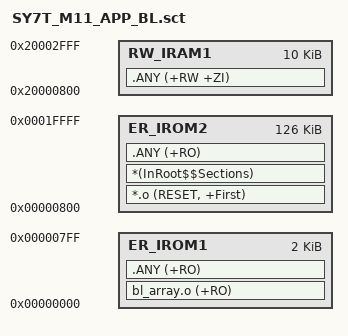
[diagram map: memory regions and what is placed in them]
; *************************************************************
; *** Scatter-Loading Description File generated by uVision ***
; *************************************************************

LR_IROM2 0x00000800 0x0001F800  {    ; load region size_region
  ER_IROM2 0x00000800 0x0001F800  {  ; load address = execution address
   *.o (RESET, +First)
   *(InRoot$$Sections)
   .ANY (+RO)
  }
  RW_IRAM1 0x20000800 0x00002800  {  ; RW data
   .ANY (+RW +ZI)
  }
}

LR_IROM1 0x00000000 0x00000800  {
  ER_IROM1 0x00000000 0x00000800  {  ; load address = execution address
    bl_array.o (+RO)
   .ANY (+RO)
  }
}
